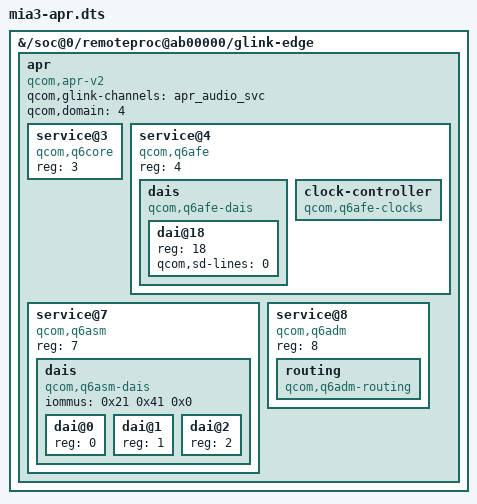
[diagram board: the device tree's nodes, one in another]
/dts-v1/;
/plugin/;
/* APR audio services on the ADSP glink edge (from sm6115.dtsi, without qcom,protection-domain:
 * qcom_pd_mapper has no sm6125 entry). 0x21 = apps_smmu in k7.dtb. Restart the ADSP after applying. */
&{/soc@0/remoteproc@ab00000/glink-edge} {
	apr {
		compatible = "qcom,apr-v2";
		qcom,glink-channels = "apr_audio_svc";
		qcom,domain = <4>;
		#address-cells = <1>;
		#size-cells = <0>;
		service@3 {
			reg = <3>;
			compatible = "qcom,q6core";
		};
		service@4 {
			compatible = "qcom,q6afe";
			reg = <4>;
			dais {
				compatible = "qcom,q6afe-dais";
				#address-cells = <1>;
				#size-cells = <0>;
				#sound-dai-cells = <1>;
				dai@18 {	/* SECONDARY_MI2S_RX, stock rx-lines 0x1 = SD0 */
					reg = <18>;
					qcom,sd-lines = <0>;
				};
			};
			clock-controller {
				compatible = "qcom,q6afe-clocks";
				#clock-cells = <2>;
			};
		};
		service@7 {
			compatible = "qcom,q6asm";
			reg = <7>;
			dais {
				compatible = "qcom,q6asm-dais";
				#address-cells = <1>;
				#size-cells = <0>;
				#sound-dai-cells = <1>;
				iommus = <0x21 0x41 0x0>;	/* stock msm-audio-ion: SID 0x41 (0x1c1 is sm6115's) */
				dai@0 { reg = <0>; };
				dai@1 { reg = <1>; };
				dai@2 { reg = <2>; };
			};
		};
		service@8 {
			compatible = "qcom,q6adm";
			reg = <8>;
			routing {
				compatible = "qcom,q6adm-routing";
				#sound-dai-cells = <0>;
			};
		};
	};
};
